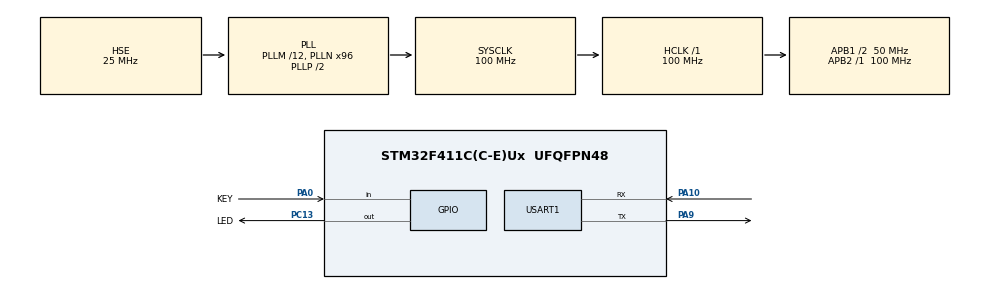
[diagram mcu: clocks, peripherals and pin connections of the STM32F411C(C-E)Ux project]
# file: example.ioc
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FREERTOS.Queues01=ledQueue,8,uint32_t,0,Dynamic,NULL,NULL
FREERTOS.Tasks01=defaultTask,24,256,StartDefaultTask,Default,NULL,Dynamic,NULL,NULL;led,9,256,ledTask,As weak,NULL,Dynamic,NULL,NULL
FREERTOS.Timers01=ledTimer,LedCallback,osTimerPeriodic,As weak,NULL,Dynamic,NULL
FREERTOS.configENABLE_FPU=1
Mcu.Family=STM32F4
Mcu.Name=STM32F411C(C-E)Ux
Mcu.Package=UFQFPN48
NVIC.PriorityGroup=NVIC_PRIORITYGROUP_4
NVIC.TIM1_TRG_COM_TIM11_IRQn=true\:15\:0\:false\:false\:true\:false\:false\:true\:true
NVIC.TimeBase=TIM1_TRG_COM_TIM11_IRQn
NVIC.TimeBaseIP=TIM11
PA0-WKUP.GPIO_Label=KEY
PA0-WKUP.GPIO_PuPd=GPIO_PULLUP
PA0-WKUP.Signal=GPIO_Input
PA10.Mode=Asynchronous
PA10.Signal=USART1_RX
PA13.Mode=Serial_Wire
PA13.Signal=SYS_JTMS-SWDIO
PA14.Mode=Serial_Wire
PA14.Signal=SYS_JTCK-SWCLK
PA9.Mode=Asynchronous
PA9.Signal=USART1_TX
PC13-ANTI_TAMP.GPIO_Label=LED
PC13-ANTI_TAMP.Signal=GPIO_Output
PH0\ -\ OSC_IN.Mode=HSE-External-Oscillator
PH0\ -\ OSC_IN.Signal=RCC_OSC_IN
PH1\ -\ OSC_OUT.Mode=HSE-External-Oscillator
PH1\ -\ OSC_OUT.Signal=RCC_OSC_OUT
ProjectManager.HeapSize=0x200
ProjectManager.StackSize=0x400
ProjectManager.TargetToolchain=CMake
RCC.48MHZClocksFreq_Value=50000000
RCC.AHBFreq_Value=100000000
RCC.APB1CLKDivider=RCC_HCLK_DIV2
RCC.APB1Freq_Value=50000000
RCC.APB1TimFreq_Value=100000000
RCC.APB2Freq_Value=100000000
RCC.APB2TimFreq_Value=100000000
RCC.CortexFreq_Value=100000000
RCC.HCLKFreq_Value=100000000
RCC.HSE_VALUE=25000000
RCC.HSI_VALUE=16000000
RCC.LSE_VALUE=32768
RCC.PLLM=12
RCC.PLLN=96
RCC.PLLSourceVirtual=RCC_PLLSOURCE_HSE
RCC.SYSCLKFreq_VALUE=100000000
RCC.SYSCLKSource=RCC_SYSCLKSOURCE_PLLCLK
RCC.VCOOutputFreq_Value=200000000
USART1.VirtualMode=VM_ASYNC
VP_FREERTOS_VS_CMSIS_V2.Mode=CMSIS_V2
VP_SYS_VS_tim11.Mode=TIM11
board=custom

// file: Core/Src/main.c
/* USER CODE BEGIN Header */
/**
  ******************************************************************************
  * @file           : main.c
  * @brief          : Main program body
  ******************************************************************************
  * @attention
  *
  * Copyright (c) 2024 STMicroelectronics.
  * All rights reserved.
  *
  * This software is licensed under terms that can be found in the LICENSE file
  * in the root directory of this software component.
  * If no LICENSE file comes with this software, it is provided AS-IS.
  *
  ******************************************************************************
  */
/* USER CODE END Header */
#include "main.h"
#include "cmsis_os.h"

/* USER CODE BEGIN Includes */
#include "cmsis_os2.h"
/* USER CODE END Includes */

UART_HandleTypeDef huart1;

/* Definitions for defaultTask */
osThreadId_t defaultTaskHandle;
const osThreadAttr_t defaultTask_attributes = {
  .name = "defaultTask",
  .stack_size = 256 * 4,
  .priority = (osPriority_t) osPriorityNormal,
};
/* Definitions for led */
osThreadId_t ledHandle;
const osThreadAttr_t led_attributes = {
  .name = "led",
  .stack_size = 256 * 4,
  .priority = (osPriority_t) osPriorityLow1,
};
/* Definitions for ledQueue */
osMessageQueueId_t ledQueueHandle;
const osMessageQueueAttr_t ledQueue_attributes = {
  .name = "ledQueue"
};
/* Definitions for ledTimer */
osTimerId_t ledTimerHandle;
const osTimerAttr_t ledTimer_attributes = {
  .name = "ledTimer"
};

void SystemClock_Config(void);
static void MX_GPIO_Init(void);
static void MX_USART1_UART_Init(void);
void StartDefaultTask(void *argument);
void ledTask(void *argument);
void LedCallback(void *argument);

/* USER CODE BEGIN PFP */
void hardware_init(void);
int app(void);
/* USER CODE END PFP */

int main(void)
{

  /* MCU Configuration--------------------------------------------------------*/

  /* Reset of all peripherals, Initializes the Flash interface and the Systick. */
  HAL_Init();

  /* Configure the system clock */
  SystemClock_Config();

  /* Initialize all configured peripherals */
  MX_GPIO_Init();
  MX_USART1_UART_Init();

  /* Init scheduler */
  osKernelInitialize();

  /* Create the timer(s) */
  /* creation of ledTimer */
  ledTimerHandle = osTimerNew(LedCallback, osTimerPeriodic, NULL, &ledTimer_attributes);

  /* Create the queue(s) */
  /* creation of ledQueue */
  ledQueueHandle = osMessageQueueNew (8, sizeof(uint32_t), &ledQueue_attributes);

  /* Create the thread(s) */
  /* creation of defaultTask */
  defaultTaskHandle = osThreadNew(StartDefaultTask, NULL, &defaultTask_attributes);

  /* creation of led */
  ledHandle = osThreadNew(ledTask, NULL, &led_attributes);

  /* Start scheduler */
  osKernelStart();

  /* We should never get here as control is now taken by the scheduler */

  /* Infinite loop */
  while (1)
  {

  }
}

void SystemClock_Config(void)
{
  RCC_OscInitTypeDef RCC_OscInitStruct = {0};
  RCC_ClkInitTypeDef RCC_ClkInitStruct = {0};

  /** Configure the main internal regulator output voltage
  */
  __HAL_RCC_PWR_CLK_ENABLE();
  __HAL_PWR_VOLTAGESCALING_CONFIG(PWR_REGULATOR_VOLTAGE_SCALE1);

  /** Initializes the RCC Oscillators according to the specified parameters
  * in the RCC_OscInitTypeDef structure.
  */
  RCC_OscInitStruct.OscillatorType = RCC_OSCILLATORTYPE_HSE;
  RCC_OscInitStruct.HSEState = RCC_HSE_ON;
  RCC_OscInitStruct.PLL.PLLState = RCC_PLL_ON;
  RCC_OscInitStruct.PLL.PLLSource = RCC_PLLSOURCE_HSE;
  RCC_OscInitStruct.PLL.PLLM = 12;
  RCC_OscInitStruct.PLL.PLLN = 96;
  RCC_OscInitStruct.PLL.PLLP = RCC_PLLP_DIV2;
  RCC_OscInitStruct.PLL.PLLQ = 4;
  if (HAL_RCC_OscConfig(&RCC_OscInitStruct) != HAL_OK)
  {
    Error_Handler();
  }

  /** Initializes the CPU, AHB and APB buses clocks
  */
  RCC_ClkInitStruct.ClockType = RCC_CLOCKTYPE_HCLK|RCC_CLOCKTYPE_SYSCLK
                              |RCC_CLOCKTYPE_PCLK1|RCC_CLOCKTYPE_PCLK2;
  RCC_ClkInitStruct.SYSCLKSource = RCC_SYSCLKSOURCE_PLLCLK;
  RCC_ClkInitStruct.AHBCLKDivider = RCC_SYSCLK_DIV1;
  RCC_ClkInitStruct.APB1CLKDivider = RCC_HCLK_DIV2;
  RCC_ClkInitStruct.APB2CLKDivider = RCC_HCLK_DIV1;

  if (HAL_RCC_ClockConfig(&RCC_ClkInitStruct, FLASH_LATENCY_3) != HAL_OK)
  {
    Error_Handler();
  }
}

static void MX_USART1_UART_Init(void)
{

  huart1.Instance = USART1;
  huart1.Init.BaudRate = 115200;
  huart1.Init.WordLength = UART_WORDLENGTH_8B;
  huart1.Init.StopBits = UART_STOPBITS_1;
  huart1.Init.Parity = UART_PARITY_NONE;
  huart1.Init.Mode = UART_MODE_TX_RX;
  huart1.Init.HwFlowCtl = UART_HWCONTROL_NONE;
  huart1.Init.OverSampling = UART_OVERSAMPLING_16;
  if (HAL_UART_Init(&huart1) != HAL_OK)
  {
    Error_Handler();
  }

}

static void MX_GPIO_Init(void)
{
  GPIO_InitTypeDef GPIO_InitStruct = {0};

  /* GPIO Ports Clock Enable */
  __HAL_RCC_GPIOC_CLK_ENABLE();
  __HAL_RCC_GPIOH_CLK_ENABLE();
  __HAL_RCC_GPIOA_CLK_ENABLE();

  /*Configure GPIO pin Output Level */
  HAL_GPIO_WritePin(LED_GPIO_Port, LED_Pin, GPIO_PIN_RESET);

  /*Configure GPIO pin : LED_Pin */
  GPIO_InitStruct.Pin = LED_Pin;
  GPIO_InitStruct.Mode = GPIO_MODE_OUTPUT_PP;
  GPIO_InitStruct.Pull = GPIO_NOPULL;
  GPIO_InitStruct.Speed = GPIO_SPEED_FREQ_LOW;
  HAL_GPIO_Init(LED_GPIO_Port, &GPIO_InitStruct);

  /*Configure GPIO pin : KEY_Pin */
  GPIO_InitStruct.Pin = KEY_Pin;
  GPIO_InitStruct.Mode = GPIO_MODE_INPUT;
  GPIO_InitStruct.Pull = GPIO_PULLUP;
  HAL_GPIO_Init(KEY_GPIO_Port, &GPIO_InitStruct);

}

void StartDefaultTask(void *argument)
{
  /* USER CODE BEGIN 5 */
  /* Infinite loop */
  if(app() != 0){
    Error_Handler();
  }
  osThreadExit();
  /* USER CODE END 5 */
}

__weak void ledTask(void *argument)
{
  for(;;)
  {
    osDelay(1);
  }
}

/* LedCallback function */
__weak void LedCallback(void *argument)
{
}

void HAL_TIM_PeriodElapsedCallback(TIM_HandleTypeDef *htim)
{
  if (htim->Instance == TIM11) {
    HAL_IncTick();
  }
}

void Error_Handler(void)
{
  __disable_irq();
  while (1)
  {
  }
}
